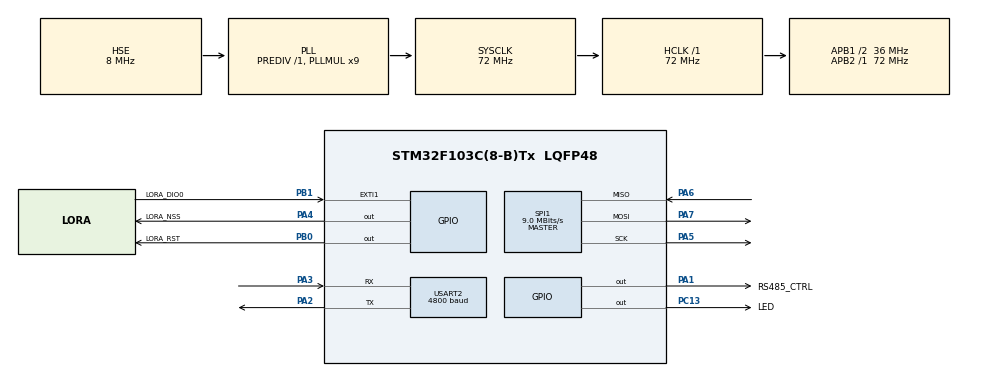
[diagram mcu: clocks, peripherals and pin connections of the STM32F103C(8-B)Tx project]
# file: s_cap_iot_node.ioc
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Dma.Request0=USART2_RX
Dma.USART2_RX.0.Direction=DMA_PERIPH_TO_MEMORY
Dma.USART2_RX.0.Instance=DMA1_Channel6
Dma.USART2_RX.0.MemDataAlignment=DMA_MDATAALIGN_BYTE
Dma.USART2_RX.0.MemInc=DMA_MINC_ENABLE
Dma.USART2_RX.0.Mode=DMA_NORMAL
Dma.USART2_RX.0.PeriphDataAlignment=DMA_PDATAALIGN_BYTE
Dma.USART2_RX.0.PeriphInc=DMA_PINC_DISABLE
Dma.USART2_RX.0.Priority=DMA_PRIORITY_MEDIUM
Mcu.Family=STM32F1
Mcu.Name=STM32F103C(8-B)Tx
Mcu.Package=LQFP48
NVIC.DMA1_Channel6_IRQn=true\:0\:0\:false\:false\:true\:false\:true\:true
NVIC.EXTI1_IRQn=true\:0\:0\:false\:false\:true\:true\:true\:true
NVIC.PriorityGroup=NVIC_PRIORITYGROUP_4
NVIC.USART2_IRQn=true\:0\:0\:false\:false\:true\:true\:true\:true
PA1.GPIO_Label=RS485_CTRL
PA1.Signal=GPIO_Output
PA13.Mode=Serial_Wire
PA13.Signal=SYS_JTMS-SWDIO
PA14.Mode=Serial_Wire
PA14.Signal=SYS_JTCK-SWCLK
PA2.Mode=Asynchronous
PA2.Signal=USART2_TX
PA3.Mode=Asynchronous
PA3.Signal=USART2_RX
PA4.GPIO_Label=LORA_NSS
PA4.PinState=GPIO_PIN_SET
PA4.Signal=GPIO_Output
PA5.Mode=Full_Duplex_Master
PA5.Signal=SPI1_SCK
PA6.Mode=Full_Duplex_Master
PA6.Signal=SPI1_MISO
PA7.Mode=Full_Duplex_Master
PA7.Signal=SPI1_MOSI
PB0.GPIO_Label=LORA_RST
PB0.PinState=GPIO_PIN_SET
PB0.Signal=GPIO_Output
PB1.GPIO_Label=LORA_DIO0
PB1.Signal=GPXTI1
PC13-TAMPER-RTC.GPIO_Label=LED
PC13-TAMPER-RTC.Signal=GPIO_Output
PD0-OSC_IN.Mode=HSE-External-Oscillator
PD0-OSC_IN.Signal=RCC_OSC_IN
PD1-OSC_OUT.Mode=HSE-External-Oscillator
PD1-OSC_OUT.Signal=RCC_OSC_OUT
ProjectManager.HeapSize=0x200
ProjectManager.StackSize=0x400
ProjectManager.TargetToolchain=STM32CubeIDE
RCC.AHBFreq_Value=72000000
RCC.APB1CLKDivider=RCC_HCLK_DIV2
RCC.APB1Freq_Value=36000000
RCC.APB1TimFreq_Value=72000000
RCC.APB2Freq_Value=72000000
RCC.APB2TimFreq_Value=72000000
RCC.HCLKFreq_Value=72000000
RCC.PLLMUL=RCC_PLL_MUL9
RCC.PLLSourceVirtual=RCC_PLLSOURCE_HSE
RCC.SYSCLKFreq_VALUE=72000000
RCC.SYSCLKSource=RCC_SYSCLKSOURCE_PLLCLK
RCC.USBFreq_Value=72000000
SPI1.BaudRatePrescaler=SPI_BAUDRATEPRESCALER_8
SPI1.CalculateBaudRate=9.0 MBits/s
SPI1.Direction=SPI_DIRECTION_2LINES
SPI1.Mode=SPI_MODE_MASTER
SPI1.VirtualType=VM_MASTER
USART2.BaudRate=4800
USART2.VirtualMode=VM_ASYNC
board=custom

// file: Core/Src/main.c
/* USER CODE BEGIN Header */
/**
  ******************************************************************************
  * @file           : main.c
  * @brief          : Main program body
  ******************************************************************************
  * @attention
  *
  * Copyright (c) 2026 STMicroelectronics.
  * All rights reserved.
  *
  * This software is licensed under terms that can be found in the LICENSE file
  * in the root directory of this software component.
  * If no LICENSE file comes with this software, it is provided AS-IS.
  *
  ******************************************************************************
  */
/* USER CODE END Header */
#include "main.h"
#include "dma.h"
#include "spi.h"
#include "usart.h"
#include "gpio.h"

/* USER CODE BEGIN Includes */
#include "utils.h"
#include "lora_config.h"
#include "rs485_config.h"
/* USER CODE END Includes */

void SystemClock_Config(void);

int main(void)
{

  /* USER CODE BEGIN 1 */
	RS485_SensorReading_t soil;
  /* USER CODE END 1 */

  /* MCU Configuration--------------------------------------------------------*/

  /* Reset of all peripherals, Initializes the Flash interface and the Systick. */
  HAL_Init();

  /* Configure the system clock */
  SystemClock_Config();

  /* Initialize all configured peripherals */
  MX_GPIO_Init();
  MX_DMA_Init();
  MX_SPI1_Init();
  MX_USART2_UART_Init();
  /* USER CODE BEGIN 2 */
  led_off();
  uint16_t lora_status = lora_init();
  if(lora_status == LORA_OK){
	  led_toggle(300,3);
  }

  RS485_Init();
  if (RS485_ReadSoilSensor(&soil) == HAL_OK)
  {
      uint16_t moisture_pct = soil.moisture / 10.0f;
      uint16_t temp_c       = soil.temperature / 10.0f;
      uint16_t ec_us     = soil.ec;

      /* Build LoRa payload directly */
  }
  /* USER CODE END 2 */

  /* Infinite loop */
  while (1)
  {

  }
}

void SystemClock_Config(void)
{
  RCC_OscInitTypeDef RCC_OscInitStruct = {0};
  RCC_ClkInitTypeDef RCC_ClkInitStruct = {0};

  /** Initializes the RCC Oscillators according to the specified parameters
  * in the RCC_OscInitTypeDef structure.
  */
  RCC_OscInitStruct.OscillatorType = RCC_OSCILLATORTYPE_HSE;
  RCC_OscInitStruct.HSEState = RCC_HSE_ON;
  RCC_OscInitStruct.HSEPredivValue = RCC_HSE_PREDIV_DIV1;
  RCC_OscInitStruct.HSIState = RCC_HSI_ON;
  RCC_OscInitStruct.PLL.PLLState = RCC_PLL_ON;
  RCC_OscInitStruct.PLL.PLLSource = RCC_PLLSOURCE_HSE;
  RCC_OscInitStruct.PLL.PLLMUL = RCC_PLL_MUL9;
  if (HAL_RCC_OscConfig(&RCC_OscInitStruct) != HAL_OK)
  {
    Error_Handler();
  }

  /** Initializes the CPU, AHB and APB buses clocks
  */
  RCC_ClkInitStruct.ClockType = RCC_CLOCKTYPE_HCLK|RCC_CLOCKTYPE_SYSCLK
                              |RCC_CLOCKTYPE_PCLK1|RCC_CLOCKTYPE_PCLK2;
  RCC_ClkInitStruct.SYSCLKSource = RCC_SYSCLKSOURCE_PLLCLK;
  RCC_ClkInitStruct.AHBCLKDivider = RCC_SYSCLK_DIV1;
  RCC_ClkInitStruct.APB1CLKDivider = RCC_HCLK_DIV2;
  RCC_ClkInitStruct.APB2CLKDivider = RCC_HCLK_DIV1;

  if (HAL_RCC_ClockConfig(&RCC_ClkInitStruct, FLASH_LATENCY_2) != HAL_OK)
  {
    Error_Handler();
  }
}

void Error_Handler(void)
{
  __disable_irq();
  while (1)
  {
  }
}
